VERSION ""

NS_ :

BS_:

BU_: BCM XXX

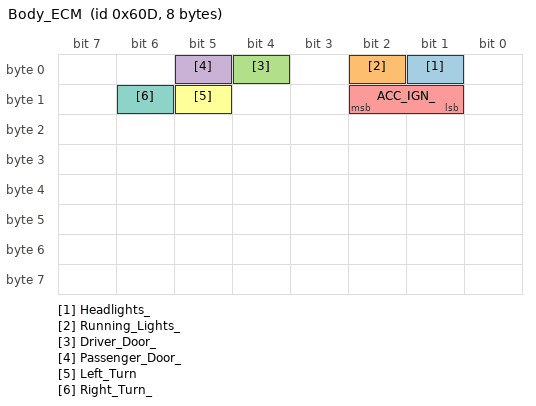
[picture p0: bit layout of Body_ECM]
BO_ 1549 Body_ECM: 8 BCM
 SG_ Headlights_ : 1|1@0+ (1,0) [0|1] "" XXX
 SG_ Running_Lights_ : 2|1@0+ (1,0) [0|1] "" XXX
 SG_ Driver_Door_ : 4|1@0+ (1,0) [0|1] "" XXX
 SG_ Passenger_Door_ : 5|1@0+ (1,0) [0|1] "" XXX
 SG_ ACC_IGN_ : 10|2@0+ (1,0) [0|1] "" XXX
 SG_ Left_Turn : 13|1@0+ (1,0) [0|1] "" XXX
 SG_ Right_Turn_ : 14|1@0+ (1,0) [0|1] "" XXX
